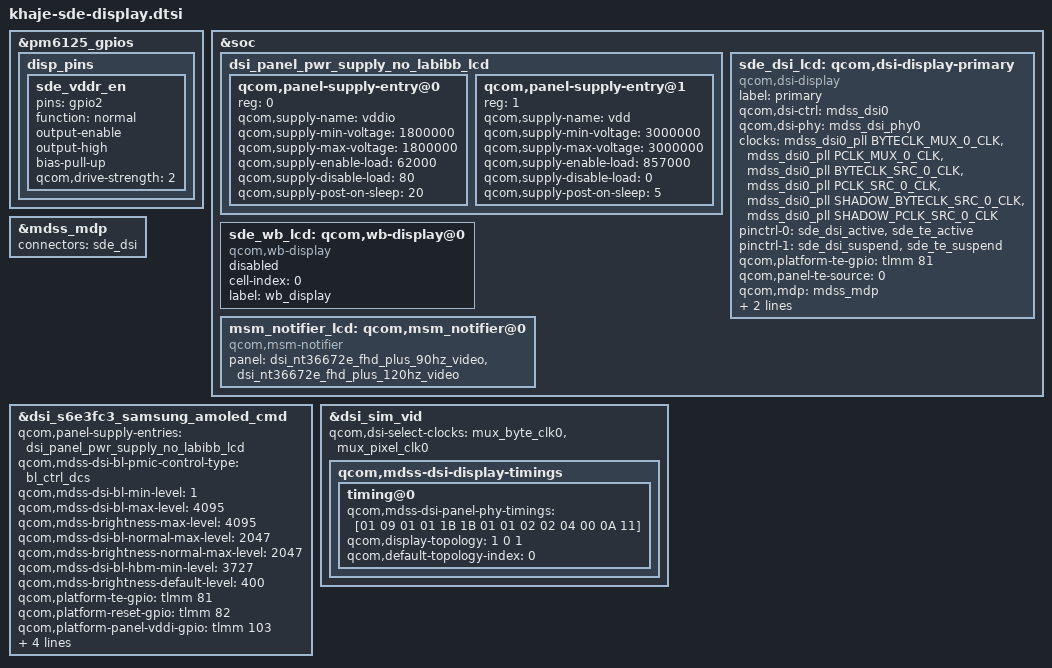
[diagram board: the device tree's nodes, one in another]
#include "dsi-panel-s6e3fc3-samsung-fhd-plus-cmd.dtsi"
/*
&tlmm {
	disp_pins {
		sde_vddr_en: sde_vddr_en {
			pins = "gpio103";
			function = "normal";
			output-enable;
			output-high;
			bias-pull-up;
			qcom,drive-strength = <2>;
			//power-source = <0>;
		};
	};
};*/

&pm6125_gpios {
	disp_pins {
		sde_vddr_en: sde_vddr_en {
			pins = "gpio2";
			function = "normal";
			output-enable;
			output-high;
			bias-pull-up;
			qcom,drive-strength = <2>;
			//power-source = <0>;
		};
	};
};

&soc {
	dsi_panel_pwr_supply_no_labibb_lcd: dsi_panel_pwr_supply_no_labibb_lcd {
		#address-cells = <1>;
		#size-cells = <0>;

		qcom,panel-supply-entry@0 {
			reg = <0>;
			qcom,supply-name = "vddio";
			qcom,supply-min-voltage = <1800000>;
			qcom,supply-max-voltage = <1800000>;
			qcom,supply-enable-load = <62000>;
			qcom,supply-disable-load = <80>;
			qcom,supply-post-on-sleep = <20>;
		};
		qcom,panel-supply-entry@1 {
			reg = <1>;
			qcom,supply-name = "vdd";
			qcom,supply-min-voltage = <3000000>;
			qcom,supply-max-voltage = <3000000>;
			qcom,supply-enable-load = <857000>;
			qcom,supply-disable-load = <0>;
			qcom,supply-post-on-sleep = <5>;
	};
};




	sde_dsi_lcd: qcom,dsi-display-primary {
		compatible = "qcom,dsi-display";
		label = "primary";
		qcom,dsi-ctrl = <&mdss_dsi0>;
		qcom,dsi-phy = <&mdss_dsi_phy0>;

		clocks = <&mdss_dsi0_pll BYTECLK_MUX_0_CLK>,
			 <&mdss_dsi0_pll PCLK_MUX_0_CLK>,
			 <&mdss_dsi0_pll BYTECLK_SRC_0_CLK>,
			 <&mdss_dsi0_pll PCLK_SRC_0_CLK>,
			 <&mdss_dsi0_pll SHADOW_BYTECLK_SRC_0_CLK>,
			 <&mdss_dsi0_pll SHADOW_PCLK_SRC_0_CLK>;
		clock-names = "mux_byte_clk0", "mux_pixel_clk0",
			"src_byte_clk0", "src_pixel_clk0",
			"shadow_byte_clk0", "shadow_pixel_clk0";
		pinctrl-names = "panel_active", "panel_suspend";
		pinctrl-0 = <&sde_dsi_active &sde_te_active>;
		pinctrl-1 = <&sde_dsi_suspend &sde_te_suspend>;

		qcom,platform-te-gpio = <&tlmm 81 0>;
		qcom,panel-te-source = <0>;

		//vddio-supply = <&L9A>;
		qcom,mdp = <&mdss_mdp>;

		qcom,dsi-default-panel =
			<&dsi_td4330_truly_v2_cmd>;
	};

	sde_wb_lcd: qcom,wb-display@0 {
		status = "disabled";
		compatible = "qcom,wb-display";
		cell-index = <0>;
		label = "wb_display";
	};

	msm_notifier_lcd: qcom,msm_notifier@0 {
		compatible = "qcom,msm-notifier";
		panel = <&dsi_nt36672e_fhd_plus_90hz_video
			&dsi_nt36672e_fhd_plus_120hz_video>;
	};
};

&mdss_mdp {
 connectors = <&sde_dsi>;
};


//&mdss_mdp {
//	connectors = <&sde_dsi_lcd>;
//};

&dsi_s6e3fc3_samsung_amoled_cmd {
	qcom,panel-supply-entries = <&dsi_panel_pwr_supply_no_labibb_lcd>;
	qcom,mdss-dsi-bl-pmic-control-type = "bl_ctrl_dcs";
	qcom,mdss-dsi-bl-min-level = <1>;
	qcom,mdss-dsi-bl-max-level = <4095>;
	qcom,mdss-brightness-max-level = <4095>;
	qcom,mdss-dsi-bl-normal-max-level = <2047>;
	qcom,mdss-brightness-normal-max-level = <2047>;
	qcom,mdss-dsi-bl-hbm-min-level = <3727>;
	qcom,mdss-brightness-default-level = <400>;
	qcom,platform-te-gpio = <&tlmm 81 0>;
	qcom,platform-reset-gpio = <&tlmm 82 0>;
	qcom,platform-panel-vddi-gpio = <&tlmm 103 0>;
	qcom,platform-panel-vci-gpio = <&tlmm 71 0>;
	qcom,platform-panel-vddr-gpio = <&pm6125_gpios 2 0>;
	qcom,dsi-select-clocks = "mux_byte_clk0", "mux_pixel_clk0";
};

&dsi_sim_vid {
	qcom,dsi-select-clocks = "mux_byte_clk0", "mux_pixel_clk0";
	qcom,mdss-dsi-display-timings {
		timing@0 {
			qcom,mdss-dsi-panel-phy-timings = [01 09 01 01 1B 1B 01
					01 02 02 04 00 0A 11];
			qcom,display-topology = <1 0 1>;
			qcom,default-topology-index = <0>;
		};
	};
};
